VERSION ""

NS_ :

BS_:

BU_: BCM VRM Power_Controller Boost_Converter Inverter

BO_ 3221225472 VECTOR__INDEPENDENT_SIG_MSG: 0 Vector__XXX
 SG_ Bus_Voltage_Tolerance : 0|8@1+ (1,0) [0|100] "%" Vector__XXX

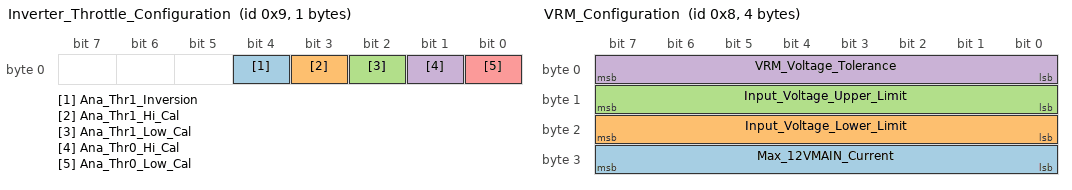
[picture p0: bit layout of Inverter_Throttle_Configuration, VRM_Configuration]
BO_ 9 Inverter_Throttle_Configuration: 1 Vector__XXX
 SG_ Ana_Thr1_Inversion : 4|1@1+ (1,0) [0|1] "" Vector__XXX
 SG_ Ana_Thr1_Hi_Cal : 3|1@1+ (1,0) [0|1] "" Vector__XXX
 SG_ Ana_Thr1_Low_Cal : 2|1@1+ (1,0) [0|1] "" Vector__XXX
 SG_ Ana_Thr0_Hi_Cal : 1|1@1+ (1,0) [0|1] "" Vector__XXX
 SG_ Ana_Thr0_Low_Cal : 0|1@1+ (1,0) [0|1] "" Vector__XXX

BO_ 8 VRM_Configuration: 4 VRM
 SG_ Max_12VMAIN_Current : 24|8@1+ (1,0) [0|254] "A" Vector__XXX
 SG_ Input_Voltage_Lower_Limit : 16|8@1+ (1,0) [0|254] "V" Vector__XXX
 SG_ Input_Voltage_Upper_Limit : 8|8@1+ (1,0) [0|254] "V" Vector__XXX
 SG_ VRM_Voltage_Tolerance : 0|8@1+ (1,0) [0|100] "%" Vector__XXX

BO_ 7 VRM_Command: 1 VRM
 SG_ VRM_Enable : 0|1@1+ (1,0) [0|1] "" Vector__XXX

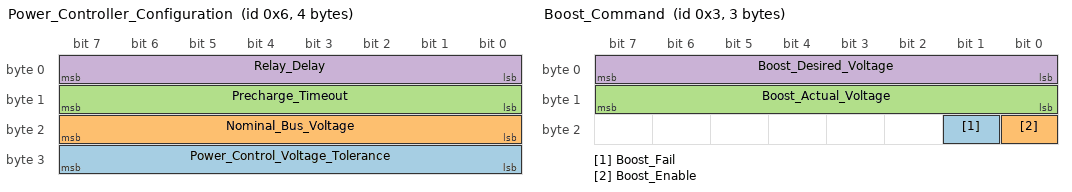
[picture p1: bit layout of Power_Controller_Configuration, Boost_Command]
BO_ 6 Power_Controller_Configuration: 4 Power_Controller
 SG_ Power_Control_Voltage_Tolerance : 24|8@1+ (1,0) [0|100] "%" Vector__XXX
 SG_ Nominal_Bus_Voltage : 16|8@1+ (1,0) [0|254] "V" Vector__XXX
 SG_ Precharge_Timeout : 8|8@1+ (1,0) [0|25] "s" Vector__XXX
 SG_ Relay_Delay : 0|8@1+ (1,0) [0|254] "ms" Vector__XXX

BO_ 5 Power_Controller_Command: 1 Power_Controller
 SG_ Power_Controller_Enable : 0|1@1+ (1,0) [0|1] "" Vector__XXX

BO_ 4 Boost_Configuration: 2 Boost_Converter
 SG_ Max_Boost_PWM : 8|8@1+ (1,0) [0|254] "" Vector__XXX
 SG_ Max_Bus_Voltage : 0|8@1+ (1,0) [0|254] "V" Vector__XXX

BO_ 3 Boost_Command: 3 Boost_Converter
 SG_ Boost_Fail : 17|1@1+ (1,0) [0|1] "" Vector__XXX
 SG_ Boost_Enable : 16|1@1+ (1,0) [0|1] "" Vector__XXX
 SG_ Boost_Actual_Voltage : 8|8@1+ (1,0) [0|254] "V" Vector__XXX
 SG_ Boost_Desired_Voltage : 0|8@1+ (1,0) [0|254] "V" Vector__XXX

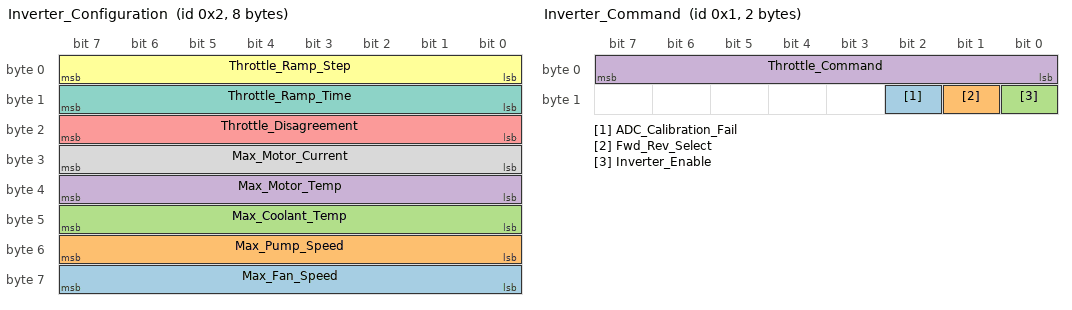
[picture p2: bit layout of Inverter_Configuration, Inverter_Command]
BO_ 2 Inverter_Configuration: 8 Inverter
 SG_ Max_Fan_Speed : 56|8@1+ (1,0) [0|100] "%" Vector__XXX
 SG_ Max_Pump_Speed : 48|8@1+ (1,0) [0|100] "%" Vector__XXX
 SG_ Max_Coolant_Temp : 40|8@1+ (1,0) [0|254] "°C" Vector__XXX
 SG_ Max_Motor_Temp : 32|8@1+ (1,0) [0|254] "°C" Vector__XXX
 SG_ Throttle_Disagreement : 16|8@1+ (1,0) [0|100] "%" Vector__XXX
 SG_ Throttle_Ramp_Step : 0|8@1+ (1,0) [0|20] "%" Vector__XXX
 SG_ Throttle_Ramp_Time : 8|8@1+ (1,0) [0|20] "ms" Vector__XXX
 SG_ Max_Motor_Current : 24|8@1+ (1,0) [0|254] "A" Vector__XXX

BO_ 1 Inverter_Command: 2 Inverter
 SG_ ADC_Calibration_Fail : 10|1@1+ (1,0) [0|1] "" Vector__XXX
 SG_ Fwd_Rev_Select : 9|1@1+ (1,0) [0|1] "" Vector__XXX
 SG_ Inverter_Enable : 8|1@1+ (1,0) [0|1] "" Vector__XXX
 SG_ Throttle_Command : 0|8@1+ (1,0) [0|100] "%" Vector__XXX

BO_TX_BU_ 4 : BCM,Boost_Converter;
BO_TX_BU_ 3 : BCM,Boost_Converter;
BO_TX_BU_ 1 : BCM,Inverter;

CM_ BO_ 3221225472 "This is a message for not used signals, created by Vector CANdb++ DBC OLE DB Provider.";
BA_DEF_  "BusType" STRING ;
BA_DEF_DEF_  "BusType" "CAN";
